VERSION ""

NS_ :

BS_:

BU_: Dash_Node Wheel_RR Wheel_RL Engine Wheel_FR Wheel_FL Main_Node

BO_ 3221225472 VECTOR__INDEPENDENT_SIG_MSG: 0 Vector__XXX
 SG_ RTC_Time : 0|32@1+ (1,0) [0|4294967295] "" Vector__XXX
 SG_ GPS_Lon : 0|64@1- (1,0) [-1.7E+308|1.7E+308] "degrees" Vector__XXX
 SG_ GPS_Lat : 0|64@1- (1,0) [-1.7E+308|1.7E+308] "degree" Vector__XXX
 SG_ Engine_Gear : 0|3@1+ (1,0) [0|7] "" Vector__XXX

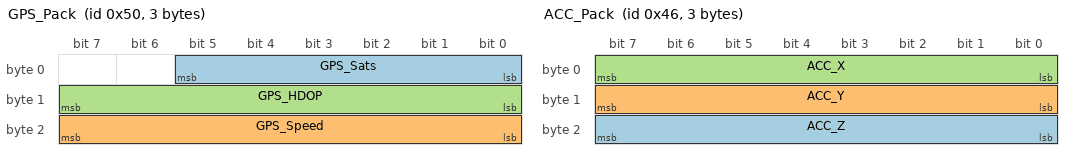
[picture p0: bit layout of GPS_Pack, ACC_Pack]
BO_ 80 GPS_Pack: 3 Main_Node
 SG_ GPS_Sats : 0|6@1+ (1,0) [0|63] "" Vector__XXX
 SG_ GPS_Speed : 16|8@1+ (1,0) [0|255] "km/h" Vector__XXX
 SG_ GPS_HDOP : 8|8@1+ (1,0) [0|255] "meter" Vector__XXX

BO_ 70 ACC_Pack: 3 Main_Node
 SG_ ACC_Z : 16|8@1- (1,0) [-128|127] "G" Vector__XXX
 SG_ ACC_Y : 8|8@1- (1,0) [-128|127] "G" Vector__XXX
 SG_ ACC_X : 0|8@1- (1,0) [-128|127] "G" Vector__XXX

BO_ 14 Engine_Error: 1 Engine
 SG_ Engine_Error : 0|1@1+ (1,0) [0|1] ""  Dash_Node,Main_Node

BO_ 12 Engine_Oil: 3 Engine
 SG_ Engine_Oil_Temp : 16|8@1- (1,78) [-50|205] "celcius"  Dash_Node,Main_Node
 SG_ Engine_Oil_Press : 0|15@1+ (1,0) [0|32767] ""  Dash_Node,Main_Node

BO_ 10 Engine_RPM: 2 Engine
 SG_ Engine_RPM : 0|15@1+ (1,0) [0|32767] ""  Dash_Node,Main_Node

BO_ 61 Brake_Rear_Pressure: 2 Wheel_RR
 SG_ Brake_Press_Rear : 0|15@1+ (1,0) [0|32767] ""  Main_Node

BO_ 60 Brake_Front_Pressure: 2 Wheel_FR
 SG_ Brake_Press_Front : 0|15@1+ (1,0) [0|32767] ""  Main_Node

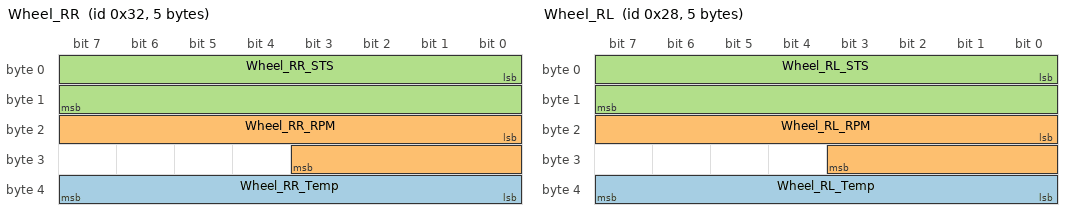
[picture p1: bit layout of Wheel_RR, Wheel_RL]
BO_ 50 Wheel_RR: 5 Wheel_RR
 SG_ Wheel_RR_Temp : 32|8@1- (1,78) [-50|205] "celcius"  Main_Node
 SG_ Wheel_RR_RPM : 16|12@1- (1,1000) [-1048|3047] ""  Main_Node
 SG_ Wheel_RR_STS : 0|16@1+ (1,0) [0|65535] ""  Main_Node

BO_ 40 Wheel_RL: 5 Wheel_RL
 SG_ Wheel_RL_Temp : 32|8@1- (1,78) [-50|205] "celcius"  Main_Node
 SG_ Wheel_RL_RPM : 16|12@1- (1,1000) [-1048|3047] ""  Main_Node
 SG_ Wheel_RL_STS : 0|16@1+ (1,0) [0|65535] ""  Main_Node

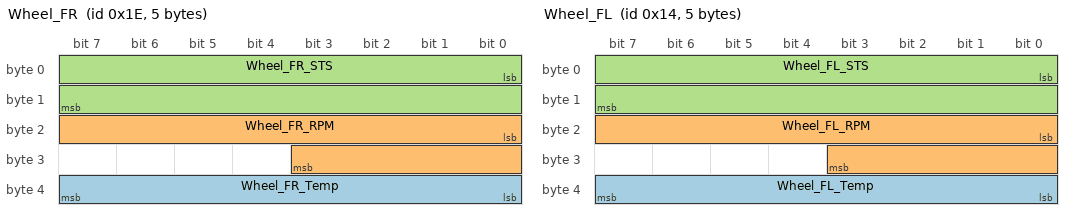
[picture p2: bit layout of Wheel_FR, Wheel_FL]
BO_ 30 Wheel_FR: 5 Wheel_FR
 SG_ Wheel_FR_Temp : 32|8@1- (1,78) [-50|205] "celcius"  Main_Node
 SG_ Wheel_FR_RPM : 16|12@1- (1,1000) [-1048|3047] ""  Main_Node
 SG_ Wheel_FR_STS : 0|16@1+ (1,0) [0|65535] ""  Main_Node

BO_ 13 Engine_Coolant: 1 Engine
 SG_ Engine_Coolant_Temp : 0|8@1- (1,78) [-50|205] "Celcius"  Dash_Node,Main_Node

BO_ 20 Wheel_FL: 5 Wheel_FL
 SG_ Wheel_FL_Temp : 32|8@1- (1,78) [-50|205] "celcius"  Main_Node
 SG_ Wheel_FL_RPM : 16|12@1- (1,1000) [-1048|3047] ""  Main_Node
 SG_ Wheel_FL_STS : 0|16@1+ (1,0) [0|65535] ""  Main_Node

CM_ BO_ 3221225472 "This is a message for not used signals, created by Vector CANdb++ DBC OLE DB Provider.";
BA_DEF_  "BusType" STRING ;
BA_DEF_DEF_  "BusType" "CAN";
SIG_VALTYPE_ 3221225472 GPS_Lon : 2;
SIG_VALTYPE_ 3221225472 GPS_Lat : 2;
